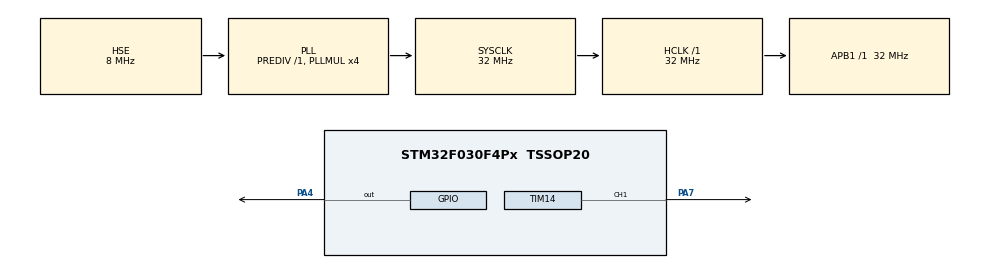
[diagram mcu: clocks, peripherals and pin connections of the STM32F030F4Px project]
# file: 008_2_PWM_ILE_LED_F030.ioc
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Mcu.Family=STM32F0
Mcu.Name=STM32F030F4Px
Mcu.Package=TSSOP20
PA13.Mode=Serial_Wire
PA13.Signal=SYS_SWDIO
PA14.Mode=Serial_Wire
PA14.Signal=SYS_SWCLK
PA4.GPIO_ModeDefaultOutputPP=GPIO_MODE_OUTPUT_PP
PA4.GPIO_PuPd=GPIO_NOPULL
PA4.GPIO_Speed=GPIO_SPEED_FREQ_MEDIUM
PA4.Signal=GPIO_Output
PA7.GPIO_ModeDefaultPP=GPIO_MODE_AF_PP
PA7.GPIO_PuPd=GPIO_NOPULL
PA7.GPIO_Speed=GPIO_SPEED_FREQ_MEDIUM
PA7.Signal=S_TIM14_CH1
PF0-OSC_IN.Mode=HSE-External-Oscillator
PF0-OSC_IN.Signal=RCC_OSC_IN
PF1-OSC_OUT.Mode=HSE-External-Oscillator
PF1-OSC_OUT.Signal=RCC_OSC_OUT
ProjectManager.HeapSize=0x200
ProjectManager.StackSize=0x400
ProjectManager.TargetToolchain=TrueSTUDIO
RCC.AHBFreq_Value=32000000
RCC.APB1Freq_Value=32000000
RCC.APB1TimFreq_Value=32000000
RCC.HCLKFreq_Value=32000000
RCC.PLLMUL=RCC_PLL_MUL4
RCC.PLLSourceVirtual=RCC_PLLSOURCE_HSE
RCC.SYSCLKFreq_VALUE=32000000
RCC.SYSCLKSource=RCC_SYSCLKSOURCE_PLLCLK
SH.S_TIM14_CH1.0=TIM14_CH1,PWM Generation1 CH1
TIM14.Channel=TIM_CHANNEL_1
TIM14.ClockDivision=TIM_CLOCKDIVISION_DIV1
TIM14.Period=99
TIM14.Prescaler=6399
VP_TIM14_VS_ClockSourceINT.Mode=Enable_Timer
VP_TIM14_VS_OPM.Mode=OPM_bit
board=custom

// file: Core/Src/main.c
/* USER CODE BEGIN Header */
/**
  ******************************************************************************
  * @file           : main.c
  * @brief          : Main program body
  ******************************************************************************
  * @attention
  *
  * Copyright (c) 2022 STMicroelectronics.
  * All rights reserved.
  *
  * This software is licensed under terms that can be found in the LICENSE file
  * in the root directory of this software component.
  * If no LICENSE file comes with this software, it is provided AS-IS.
  *
  ******************************************************************************
  */
/* USER CODE END Header */
#include "main.h"

 TIM_HandleTypeDef htim14;

void SystemClock_Config(void);
static void MX_GPIO_Init(void);
static void MX_TIM14_Init(void);
/* USER CODE BEGIN PFP */
int x;
/* USER CODE END PFP */

int main(void)
{

  /* MCU Configuration--------------------------------------------------------*/

  /* Reset of all peripherals, Initializes the Flash interface and the Systick. */
  HAL_Init();

  /* Configure the system clock */
  SystemClock_Config();

  /* Initialize all configured peripherals */
  MX_GPIO_Init();
  MX_TIM14_Init();
  /* USER CODE BEGIN 2 */

  HAL_TIM_PWM_Start(&htim14, TIM_CHANNEL_1);

  /* USER CODE END 2 */

  /* Infinite loop */
  while (1)
  {
	      /* USER CODE END WHILE */
/*
	  	      for(x=0; x<256; x=x+1)
	  	      {
	  	        __HAL_TIM_SET_COMPARE(&htim14,TIM_CHANNEL_1, x);
	  	        HAL_Delay(100);
	  	      }
	  	      for(x=256; x>0; x=x-1)
	  	      {
	  	        __HAL_TIM_SET_COMPARE(&htim14,TIM_CHANNEL_1, x);
	  	        HAL_Delay(100);
	  	      }
	  	      */
	  HAL_GPIO_WritePin(GPIOA, GPIO_PIN_4, GPIO_PIN_SET);
	  HAL_Delay(1000);
	  HAL_GPIO_WritePin(GPIOA, GPIO_PIN_4, GPIO_PIN_RESET);
	  HAL_Delay(1000);

	      /* USER CODE BEGIN 3 */
	    }
    /* USER CODE BEGIN 3 */

  /* USER CODE END 3 */
}

void SystemClock_Config(void)
{
  RCC_OscInitTypeDef RCC_OscInitStruct = {0};
  RCC_ClkInitTypeDef RCC_ClkInitStruct = {0};

  /** Initializes the RCC Oscillators according to the specified parameters
  * in the RCC_OscInitTypeDef structure.
  */
  RCC_OscInitStruct.OscillatorType = RCC_OSCILLATORTYPE_HSE;
  RCC_OscInitStruct.HSEState = RCC_HSE_ON;
  RCC_OscInitStruct.PLL.PLLState = RCC_PLL_ON;
  RCC_OscInitStruct.PLL.PLLSource = RCC_PLLSOURCE_HSE;
  RCC_OscInitStruct.PLL.PLLMUL = RCC_PLL_MUL4;
  RCC_OscInitStruct.PLL.PREDIV = RCC_PREDIV_DIV1;
  if (HAL_RCC_OscConfig(&RCC_OscInitStruct) != HAL_OK)
  {
    Error_Handler();
  }

  /** Initializes the CPU, AHB and APB buses clocks
  */
  RCC_ClkInitStruct.ClockType = RCC_CLOCKTYPE_HCLK|RCC_CLOCKTYPE_SYSCLK
                              |RCC_CLOCKTYPE_PCLK1;
  RCC_ClkInitStruct.SYSCLKSource = RCC_SYSCLKSOURCE_PLLCLK;
  RCC_ClkInitStruct.AHBCLKDivider = RCC_SYSCLK_DIV1;
  RCC_ClkInitStruct.APB1CLKDivider = RCC_HCLK_DIV1;

  if (HAL_RCC_ClockConfig(&RCC_ClkInitStruct, FLASH_LATENCY_1) != HAL_OK)
  {
    Error_Handler();
  }
}

static void MX_TIM14_Init(void)
{

  TIM_OC_InitTypeDef sConfigOC = {0};

  htim14.Instance = TIM14;
  htim14.Init.Prescaler = 6399;
  htim14.Init.CounterMode = TIM_COUNTERMODE_UP;
  htim14.Init.Period = 99;
  htim14.Init.ClockDivision = TIM_CLOCKDIVISION_DIV1;
  htim14.Init.AutoReloadPreload = TIM_AUTORELOAD_PRELOAD_DISABLE;
  if (HAL_TIM_Base_Init(&htim14) != HAL_OK)
  {
    Error_Handler();
  }
  if (HAL_TIM_PWM_Init(&htim14) != HAL_OK)
  {
    Error_Handler();
  }
  if (HAL_TIM_OnePulse_Init(&htim14, TIM_OPMODE_SINGLE) != HAL_OK)
  {
    Error_Handler();
  }
  sConfigOC.OCMode = TIM_OCMODE_PWM1;
  sConfigOC.Pulse = 0;
  sConfigOC.OCPolarity = TIM_OCPOLARITY_HIGH;
  sConfigOC.OCFastMode = TIM_OCFAST_DISABLE;
  if (HAL_TIM_PWM_ConfigChannel(&htim14, &sConfigOC, TIM_CHANNEL_1) != HAL_OK)
  {
    Error_Handler();
  }
  HAL_TIM_MspPostInit(&htim14);

}

static void MX_GPIO_Init(void)
{
  GPIO_InitTypeDef GPIO_InitStruct = {0};

  /* GPIO Ports Clock Enable */
  __HAL_RCC_GPIOF_CLK_ENABLE();
  __HAL_RCC_GPIOA_CLK_ENABLE();

  /*Configure GPIO pin Output Level */
  HAL_GPIO_WritePin(GPIOA, GPIO_PIN_4, GPIO_PIN_RESET);

  /*Configure GPIO pin : PA4 */
  GPIO_InitStruct.Pin = GPIO_PIN_4;
  GPIO_InitStruct.Mode = GPIO_MODE_OUTPUT_PP;
  GPIO_InitStruct.Pull = GPIO_NOPULL;
  GPIO_InitStruct.Speed = GPIO_SPEED_FREQ_MEDIUM;
  HAL_GPIO_Init(GPIOA, &GPIO_InitStruct);

}

void Error_Handler(void)
{
  __disable_irq();
  while (1)
  {
  }
}
